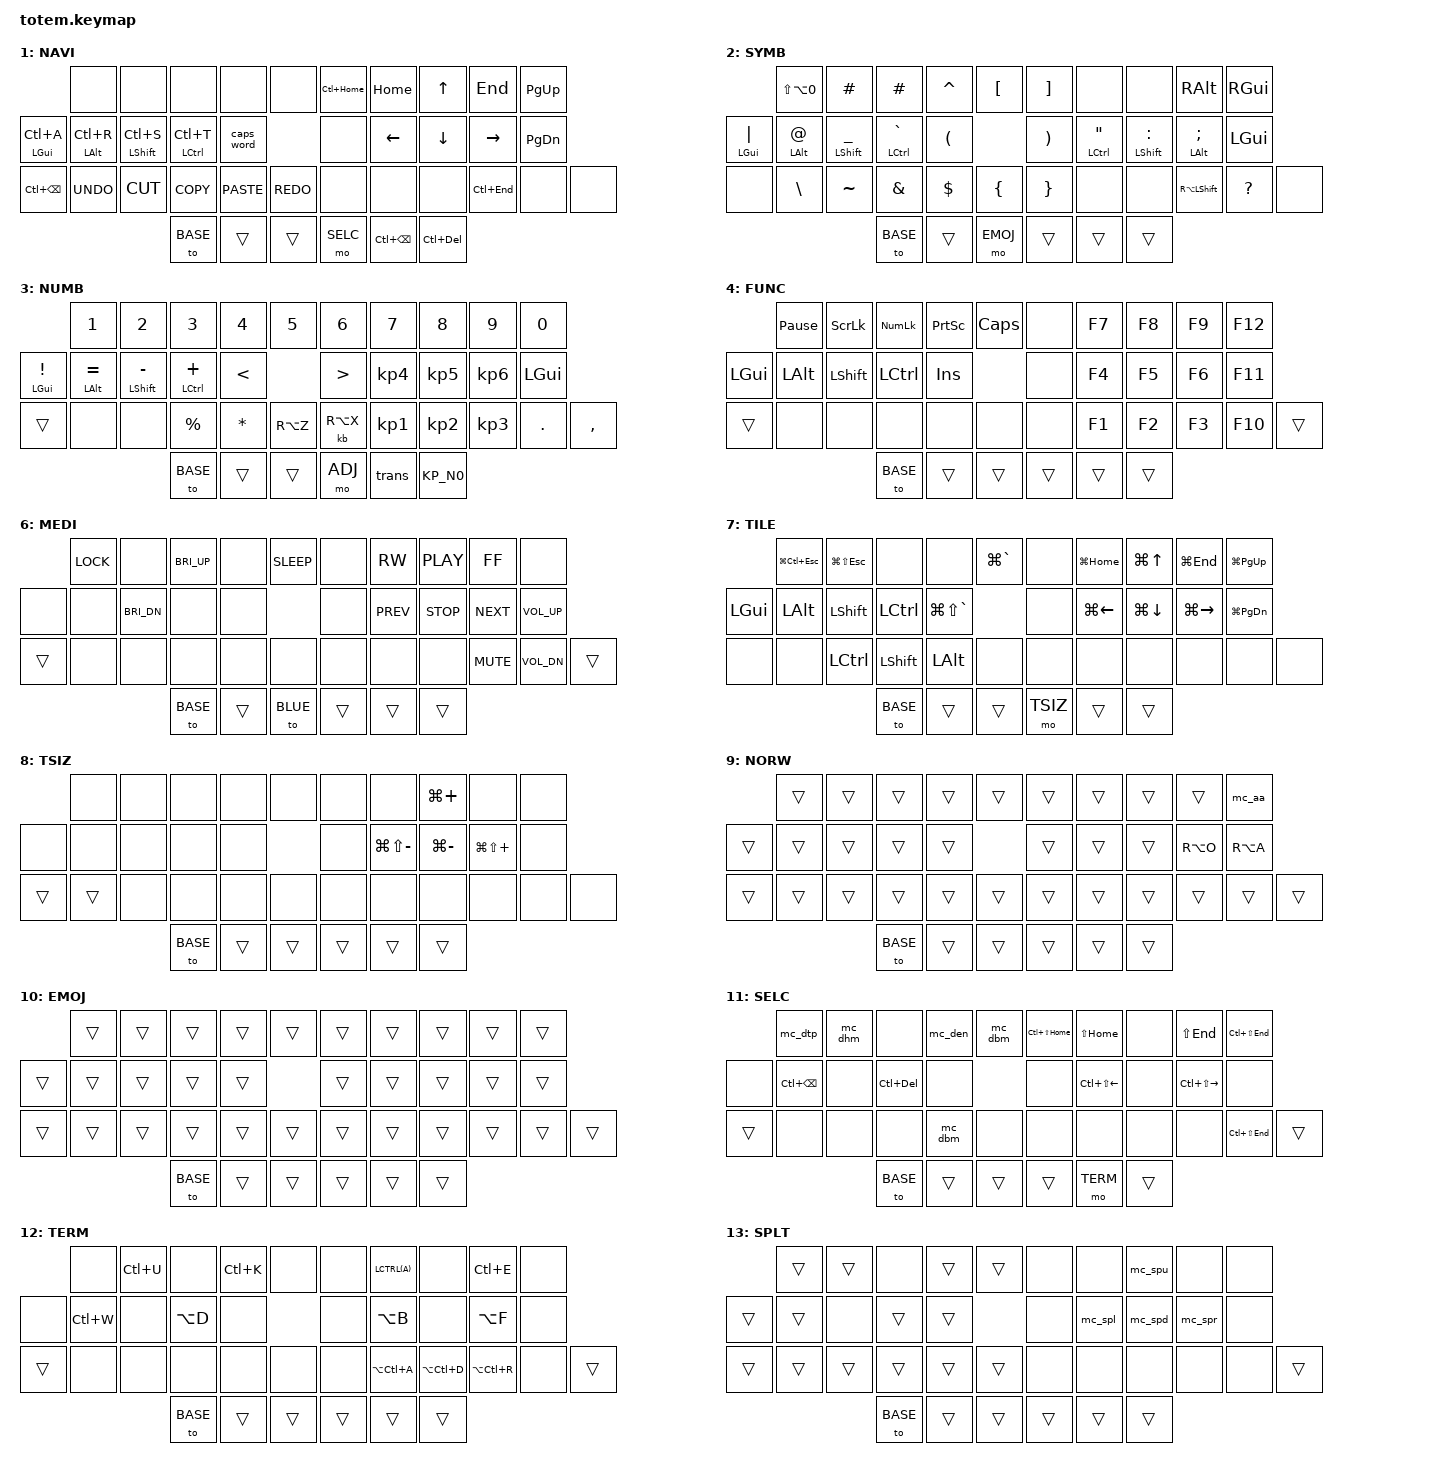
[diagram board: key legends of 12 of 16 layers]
//
//                                                        ▀▀▀▀▀     ▀▀▀▀▀          ▀▀█▀▀
//                                                        ▄▀▀▀▄  ▄  ▄▀▀▀▄  ▄  ▄▀▀▀▄  █  ▄▀▀▀▄
//                                                        █   █  █  █   █  █  █   █  █  █   █
//                                                         ▀▀▀   █   ▀▀▀   █   ▀▀▀   ▀   ▀▀▀
//                                                               █      ▄▄▄█▄▄▄    █   █
//                                                               ▀      █  █  █     █▄█
//                                                             ▀▀▀▀▀    █  █  █      ▀
//                                                                      ▀  ▀  ▀
//
// ▄▄▄▄▄▄▄▄▄▄▄▄▄▄▄▄▄▄▄▄▄▄▄▄▄▄▄▄▄▄▄▄▄▄▄▄▄▄▄▄▄▄▄▄▄▄▄▄▄▄▄▄▄▄▄▄▄▄▄▄▄▄▄▄▄▄▄▄▄▄▄▄▄▄▄▄▄▄▄▄▄▄▄▄▄▄▄▄▄▄▄▄▄▄▄▄▄▄▄▄▄▄▄▄▄▄▄▄▄▄▄▄▄▄▄▄▄▄▄▄▄▄▄▄▄▄▄▄▄▄▄▄▄▄▄▄▄▄▄▄▄▄▄▄▄▄▄▄▄


#include <behaviors.dtsi>
#include <dt-bindings/zmk/keys.h>
#include <dt-bindings/zmk/bt.h>
#include <dt-bindings/zmk/outputs.h>

#define BASE 0
#define NAVI 1
#define SYMB 2
#define NUMB 3
#define FUNC 4
#define CODE 5
#define MEDI 6
#define TILE 7
#define TSIZ 8
#define NORW 9
#define EMOJ 10
#define SELC 11
#define TERM 12
#define SPLT 13
#define QWER 14
#define BLUE 15

&mt {
  quick-tap-ms = <100>;
  global-quick-tap;
  flavor = "tap-preferred";
  tapping-term-ms = <170>;
};

/ {
   behaviors {
        td_rs: tap_dance_reset {
            compatible = "zmk,behavior-tap-dance";
            #binding-cells = <0>;
            tapping-term-ms = <200>;
            bindings = <&none>, <&sys_reset>;
        };
        td_bo: tap_dance_boot {
            compatible = "zmk,behavior-tap-dance";
            #binding-cells = <0>;
            tapping-term-ms = <200>;
            bindings = <&none>, <&bootloader>;
        };
    };

    combos {
            compatible = "zmk,combos";
            combo_esc {
                timeout-ms = <50>;
                key-positions = <0 1>;
                bindings = <&kp ESC>;
            };
    };

    macros {
        mc_aa: macro_aa {
            label = "Å";
            compatible = "zmk,behavior-macro";
            #binding-cells = <1>;
            bindings
                = <&macro_press &kp LGUI>
                , <&macro_tap &kp A>
                , <&macro_release &kp LGUI>
                , <&macro_tap &kp A>
                ;
        };
        vsc: vscode_cmd {
            #binding-cells = <2>;
            compatible = "zmk,behavior-macro-one-param";
            bindings =
                <&kp LC(K)>,
                <&macro_param_1to1 &kp MACRO_PLACEHOLDER>;
        };
        mc_spl: macro_split_left {
            label = "SPLIT_LEFT";
            compatible = "zmk,behavior-macro";
            #binding-cells = <3>;
            bindings
                = <&macro_press &kp LCTRL>
                , <&macro_tap &kp K>
                , <&macro_release &kp LCTRL>
                , <&macro_press &kp LSHFT>
                , <&macro_tap &kp LEFT>
                , <&macro_release &kp LSHFT>
                ;
        };
        mc_spr: macro_split_right {
            label = "SPLIT_RIGHT";
            compatible = "zmk,behavior-macro";
            #binding-cells = <4>;
            bindings
                = <&macro_press &kp LCTRL>
                , <&macro_tap &kp K>
                , <&macro_release &kp LCTRL>
                , <&macro_press &kp LSHFT>
                , <&macro_tap &kp RIGHT>
                , <&macro_release &kp LSHFT>
                ;
        };
        mc_spu macro_split_up {
            label = "SPLIT_UP";
            compatible = "zmk,behavior-macro";
            #binding-cells = <5>;
            bindings
                = <&macro_press &kp LCTRL>
                , <&macro_tap &kp K>
                , <&macro_release &kp LCTRL>
                , <&macro_press &kp LSHFT>
                , <&macro_tap &kp UP>
                , <&macro_release &kp LSHFT>
                ;
        };
        mc_spd: macro_split_down {
            label = "SPLIT_DOWN";
            compatible = "zmk,behavior-macro";
            #binding-cells = <6>;
            bindings
                = <&macro_press &kp LCTRL>
                , <&macro_tap &kp K>
                , <&macro_release &kp LCTRL>
                , <&macro_press &kp LSHFT>
                , <&macro_tap &kp DOWN>
                , <&macro_release &kp LSHFT>
                ;
        };
        mc_zen: macro_zen {
            label = "ZEN";
            compatible = "zmk,behavior-macro";
            #binding-cells = <7>;
            bindings
                = <&macro_press &kp LCTRL>
                , <&macro_tap &kp K>
                , <&macro_release &kp LCTRL>
                , <&macro_tap &kp Z>
                ;
        };
        mc_dhm: macro_del_home {
            label = "DELHOME";
            compatible = "zmk,behavior-macro";
            #binding-cells = <8>;
            bindings
                = <&macro_press &kp LSHFT>
                , <&macro_tap &kp HOME>
                , <&macro_release &kp LSHFT>
                , <&macro_tap &kp DEL>
                ;
        };
        mc_den: macro_del_end {
            label = "DELEND";
            compatible = "zmk,behavior-macro";
            #binding-cells = <9>;
            bindings
                = <&macro_press &kp LSHFT>
                , <&macro_tap &kp END>
                , <&macro_release &kp LSHFT>
                , <&macro_tap &kp DEL>
                ;
        };
        mc_dtp: macro_del_top {
            label = "DELTOP";
            compatible = "zmk,behavior-macro";
            #binding-cells = <10>;
            bindings
                = <&macro_press &kp LSHFT>
                , <&macro_press &kp LCTRL>
                , <&macro_tap &kp HOME>
                , <&macro_release &kp LCTRL>
                , <&macro_release &kp LSHFT>
                , <&macro_tap &kp DEL>
                ;
        };
        mc_dbm: macro_del_btm {
            label = "DELEND";
            compatible = "zmk,behavior-macro";
            #binding-cells = <11>;
            bindings
                = <&macro_press &kp LSHFT>
                , <&macro_press &kp LCTRL>
                , <&macro_tap &kp END>
                , <&macro_release &kp LCTRL>
                , <&macro_release &kp LSHFT>
                , <&macro_tap &kp DEL>
                ;
        };
        mc_sav: macro_save_file {
            label = "SAVE_FILE";
            compatible = "zmk,behavior-macro";
            #binding-cells = <12>;
            bindings
                = <&macro_press &kp LCTRL>
                , <&macro_tap &kp K>
                , <&macro_release &kp LCTRL>
                , <&macro_tap &kp S>
                ;
        };
    };

        keymap {
                compatible = "zmk,keymap";
// ▄▄▄▄▄▄▄▄▄▄▄▄▄▄▄▄▄▄▄▄▄▄▄▄▄▄▄▄▄▄▄▄▄▄▄▄▄▄▄▄▄▄▄▄▄▄▄▄▄▄▄▄▄▄▄▄▄▄▄▄▄▄▄▄▄▄▄▄▄▄▄▄▄▄▄▄▄▄▄▄▄▄▄▄▄▄▄▄▄▄▄▄▄▄▄▄▄▄▄▄▄▄▄▄▄▄▄▄▄▄▄▄▄▄▄▄▄▄▄▄▄▄▄▄▄▄▄▄▄▄▄▄▄▄▄▄▄▄▄▄▄▄▄▄▄▄▄▄▄

                base_layer {
// ┏━━━━━━━━━━━━━━━━━━━━━━━━━━━━━━━━━━━━━━━┓
label= "BASE"                              ;
// ┗━━━━━━━━━━━━━━━━━━━━━━━━━━━━━━━━━━━━━━━┛
//             ┏━━━━━━━━━━━┳━━━━━━━━━━━┳━━━━━━━━━━━┳━━━━━━━━━━━┳━━━━━━━━━━━┓   ┏━━━━━━━━━━━┳━━━━━━━━━━━┳━━━━━━━━━━━┳━━━━━━━━━━━┳━━━━━━━━━━━┓
//             ┃     Q     ┃     W     ┃     F     ┃     P     ┃     B     ┃   ┃     J     ┃     L     ┃     O     ┃     Y     ┃     '     ┃
//             ┣━━━━━━━━━━━╋━━━━━━━━━━━╋━━━━━━━━━━━╋━━━━━━━━━━━╋━━━━━━━━━━━┫   ┣━━━━━━━━━━━╋━━━━━━━━━━━╋━━━━━━━━━━━╋━━━━━━━━━━━╋━━━━━━━━━━━┫
//             ┃     A     ┃     R     ┃     S     ┃     T     ┃     G     ┃   ┃     M     ┃     N     ┃     E     ┃     I     ┃     U     ┃
// ┏━━━━━━━━━━━╋━━━━━━━━━━━╋━━━━━━━━━━━╋━━━━━━━━━━━╋━━━━━━━━━━━╋━━━━━━━━━━━┫   ┣━━━━━━━━━━━╋━━━━━━━━━━━╋━━━━━━━━━━━╋━━━━━━━━━━━╋━━━━━━━━━━━╋━━━━━━━━━━━┓
// ┃    BSPC   ┃     Z     ┃     X     ┃     C     ┃     D     ┃     V     ┃   ┃     K     ┃     H     ┃     ,     ┃     .     ┃     /     ┃           ┃
// ┗━━━━━━━━━━━┻━━━━━━━━━━━┻━━━━━━━━━━━╋━━━━━━━━━━━╋━━━━━━━━━━━╋━━━━━━━━━━━┫   ┣━━━━━━━━━━━╋━━━━━━━━━━━╋━━━━━━━━━━━╋━━━━━━━━━━━┻━━━━━━━━━━━┻━━━━━━━━━━━┛
//                                     ┃    ESC    ┃    SPC    ┃    TAB    ┃   ┃   ENTER   ┃    BSPC   ┃    DEL    ┃
//                                     ┗━━━━━━━━━━━┻━━━━━━━━━━━┻━━━━━━━━━━━┛   ┗━━━━━━━━━━━┻━━━━━━━━━━━┻━━━━━━━━━━━┛
//             ┏━━━━━━━━━━━┳━━━━━━━━━━━┳━━━━━━━━━━━┳━━━━━━━━━━━┳━━━━━━━━━━━┓   ┏━━━━━━━━━━━┳━━━━━━━━━━━┳━━━━━━━━━━━┳━━━━━━━━━━━┳━━━━━━━━━━━┓
//             ┃     ⌘R    ┃    ⌥R     ┃    ⇧R     ┃    ^R     ┃           ┃   ┃           ┃    ^R     ┃    ⇧R     ┃    ⌥R     ┃     ⌘R    ┃
//             ┣━━━━━━━━━━━╋━━━━━━━━━━━╋━━━━━━━━━━━╋━━━━━━━━━━━╋━━━━━━━━━━━┫   ┣━━━━━━━━━━━╋━━━━━━━━━━━╋━━━━━━━━━━━╋━━━━━━━━━━━╋━━━━━━━━━━━┫
//             ┃     ⌘     ┃    ⎇     ┃     ⇧     ┃     ^     ┃           ┃   ┃           ┃     ^     ┃     ⇧     ┃    ⎇     ┃     ⌘     ┃
// ┏━━━━━━━━━━━╋━━━━━━━━━━━╋━━━━━━━━━━━╋━━━━━━━━━━━╋━━━━━━━━━━━╋━━━━━━━━━━━┫   ┣━━━━━━━━━━━╋━━━━━━━━━━━╋━━━━━━━━━━━╋━━━━━━━━━━━╋━━━━━━━━━━━╋━━━━━━━━━━━┓
// ┃           ┃   TILE    ┃     ⎄     ┃   MEH     ┃   HYP     ┃           ┃   ┃           ┃    HYP    ┃    MEH    ┃     ⎄     ┃    MED    ┃    NOR    ┃
// ┗━━━━━━━━━━━┻━━━━━━━━━━━┻━━━━━━━━━━━╋━━━━━━━━━━━╋━━━━━━━━━━━╋━━━━━━━━━━━┫   ┣━━━━━━━━━━━╋━━━━━━━━━━━╋━━━━━━━━━━━╋━━━━━━━━━━━┻━━━━━━━━━━━┻━━━━━━━━━━━┛
//                                     ┃    FUN    ┃    NUM    ┃    NAV    ┃   ┃    SYM    ┃    NUM    ┃   CODE    ┃
//                                     ┗━━━━━━━━━━━┻━━━━━━━━━━━┻━━━━━━━━━━━┛   ┗━━━━━━━━━━━┻━━━━━━━━━━━┻━━━━━━━━━━━┛
 bindings = <
// ╷           ╷           ╷           ╷           ╷             ╷         ╷   ╷           ╷           ╷           ╷           ╷           ╷           ╷

                &mt RGUI Q  &mt RALT W  &mt RSHFT F &mt RCTRL P    &kp B          &kp J        &mt RCTRL L &mt RSHFT O &mt RALT Y  &mt RGUI SQT
                &mt LGUI A  &mt LALT R  &mt LSHFT S &mt LCTRL T    &kp G          &kp M        &mt LCTRL N &mt LSHFT E &mt LALT I  &mt LGUI U
    &kp BSPC    &lt TILE Z  &mt LS(RALT) X  &mt LS(LA(LCTRL)) C  &mt LS(LA(LC(LG))) D  &kp V  &kp K  &mt LS(LA(LC(LG))) H  &mt LS(LA(LCTRL)) COMMA  &mt LS(RALT) DOT  &lt MEDI FSLH  &mo NORW
                                        &lt FUNC ESC     &lt NUMB SPACE &lt NAVI TAB   &lt SYMB RET &lt NUMB BSPC    &lt CODE DEL
                        >;
                };

// ▄▄▄▄▄▄▄▄▄▄▄▄▄▄▄▄▄▄▄▄▄▄▄▄▄▄▄▄▄▄▄▄▄▄▄▄▄▄▄▄▄▄▄▄▄▄▄▄▄▄▄▄▄▄▄▄▄▄▄▄▄▄▄▄▄▄▄▄▄▄▄▄▄▄▄▄▄▄▄▄▄▄▄▄▄▄▄▄▄▄▄▄▄▄▄▄▄▄▄▄▄▄▄▄▄▄▄▄▄▄▄▄▄▄▄▄▄▄▄▄▄▄▄▄▄▄▄▄▄▄▄▄▄▄▄▄▄▄▄▄▄▄▄▄▄▄▄▄▄


                nav_layer {
// ┏━━━━━━━━━━━━━━━━━━━━━━━━━━━━━━━━━━━━━━━┓
label= "NAVI"                              ;
// ┗━━━━━━━━━━━━━━━━━━━━━━━━━━━━━━━━━━━━━━━┛
//             ┏━━━━━━━━━━━┳━━━━━━━━━━━┳━━━━━━━━━━━┳━━━━━━━━━━━┳━━━━━━━━━━━┓   ┏━━━━━━━━━━━┳━━━━━━━━━━━┳━━━━━━━━━━━┳━━━━━━━━━━━┳━━━━━━━━━━━┓
//             ┃           ┃           ┃           ┃           ┃           ┃   ┃    TOP    ┃   HOME    ┃    UP     ┃   END     ┃   PG_UP   ┃
//             ┣━━━━━━━━━━━╋━━━━━━━━━━━╋━━━━━━━━━━━╋━━━━━━━━━━━╋━━━━━━━━━━━┫   ┣━━━━━━━━━━━╋━━━━━━━━━━━╋━━━━━━━━━━━╋━━━━━━━━━━━╋━━━━━━━━━━━┫
//             ┃   SELECT  ┃   RELOAD  ┃    SAVE   ┃  NEW TAB  ┃ CAPS WORD ┃   ┃           ┃   LEFT    ┃    DOWN   ┃   RIGHT   ┃   PG_DN   ┃
// ┏━━━━━━━━━━━╋━━━━━━━━━━━╋━━━━━━━━━━━╋━━━━━━━━━━━╋━━━━━━━━━━━╋━━━━━━━━━━━┫   ┣━━━━━━━━━━━╋━━━━━━━━━━━╋━━━━━━━━━━━╋━━━━━━━━━━━╋━━━━━━━━━━━╋━━━━━━━━━━━┓
// ┃^BACKSPACE ┃    UNDO   ┃    CUT    ┃   COPY    ┃   PASTE   ┃   REDO    ┃   ┃           ┃           ┃           ┃   BTTM    ┃           ┃           ┃
// ┗━━━━━━━━━━━┻━━━━━━━━━━━┻━━━━━━━━━━━╋━━━━━━━━━━━╋━━━━━━━━━━━╋━━━━━━━━━━━┫   ┣━━━━━━━━━━━╋━━━━━━━━━━━╋━━━━━━━━━━━╋━━━━━━━━━━━┻━━━━━━━━━━━┻━━━━━━━━━━━┛
//                                     ┃           ┃           ┃           ┃   ┃   SELECT  ┃^BACKSPACE ┃   ^ DEL   ┃
//                                     ┗━━━━━━━━━━━┻━━━━━━━━━━━┻━━━━━━━━━━━┛   ┗━━━━━━━━━━━┻━━━━━━━━━━━┻━━━━━━━━━━━┛
 bindings = <
// ╷           ╷           ╷           ╷           ╷           ╷           ╷   ╷           ╷           ╷           ╷           ╷           ╷           ╷

                &none       &none       &none       &none       &none           &kp LC(HOME)  &kp HOME  &kp UP      &kp END     &kp PG_UP
       &mt LGUI LC(A)  &mt LALT LC(R)  &mt LSHFT LC(S)  &mt LCTRL LC(T)  &caps_word      &none  &kp LEFT  &kp DOWN  &kp RIGHT   &kp PG_DN
    &kp LC(BSPC)  &kp K_UNDO  &kp K_CUT  &kp K_COPY  &kp K_PASTE  &kp K_REDO    &none       &none        &none      &kp LC(END)  &none       &none
                                        &to BASE    &trans      &trans          &mo SELC    &kp LC(BSPC)  &kp LC(DEL)
                        >;
                };

// ▄▄▄▄▄▄▄▄▄▄▄▄▄▄▄▄▄▄▄▄▄▄▄▄▄▄▄▄▄▄▄▄▄▄▄▄▄▄▄▄▄▄▄▄▄▄▄▄▄▄▄▄▄▄▄▄▄▄▄▄▄▄▄▄▄▄▄▄▄▄▄▄▄▄▄▄▄▄▄▄▄▄▄▄▄▄▄▄▄▄▄▄▄▄▄▄▄▄▄▄▄▄▄▄▄▄▄▄▄▄▄▄▄▄▄▄▄▄▄▄▄▄▄▄▄▄▄▄▄▄▄▄▄▄▄▄▄▄▄▄▄▄▄▄▄▄▄▄▄


                symbol_layer {
// ┏━━━━━━━━━━━━━━━━━━━━━━━━━━━━━━━━━━━━━━━┓
label= "SYMB"                              ;
// ┗━━━━━━━━━━━━━━━━━━━━━━━━━━━━━━━━━━━━━━━┛
//             ┏━━━━━━━━━━━┳━━━━━━━━━━━┳━━━━━━━━━━━┳━━━━━━━━━━━┳━━━━━━━━━━━┓   ┏━━━━━━━━━━━┳━━━━━━━━━━━┳━━━━━━━━━━━┳━━━━━━━━━━━┳━━━━━━━━━━━┓
//             ┃     °     ┃     #     ┃     £     ┃     ˆ     ┃     [     ┃   ┃     ]     ┃           ┃           ┃           ┃           ┃
//             ┣━━━━━━━━━━━╋━━━━━━━━━━━╋━━━━━━━━━━━╋━━━━━━━━━━━╋━━━━━━━━━━━┫   ┣━━━━━━━━━━━╋━━━━━━━━━━━╋━━━━━━━━━━━╋━━━━━━━━━━━╋━━━━━━━━━━━┫
//             ┃     |     ┃     @     ┃     _     ┃     `     ┃     (     ┃   ┃     )     ┃     "     ┃     :     ┃     ;     ┃           ┃
// ┏━━━━━━━━━━━╋━━━━━━━━━━━╋━━━━━━━━━━━╋━━━━━━━━━━━╋━━━━━━━━━━━╋━━━━━━━━━━━┫   ┣━━━━━━━━━━━╋━━━━━━━━━━━╋━━━━━━━━━━━╋━━━━━━━━━━━╋━━━━━━━━━━━╋━━━━━━━━━━━┓
// ┃           ┃     \     ┃     ~     ┃     &     ┃     $     ┃     {     ┃   ┃     }     ┃           ┃           ┃           ┃     ?     ┃           ┃
// ┗━━━━━━━━━━━┻━━━━━━━━━━━┻━━━━━━━━━━━╋━━━━━━━━━━━╋━━━━━━━━━━━╋━━━━━━━━━━━┫   ┣━━━━━━━━━━━╋━━━━━━━━━━━╋━━━━━━━━━━━╋━━━━━━━━━━━┻━━━━━━━━━━━┻━━━━━━━━━━━┛
//                                     ┃           ┃           ┃   EMOJI   ┃   ┃           ┃           ┃           ┃
//                                     ┗━━━━━━━━━━━┻━━━━━━━━━━━┻━━━━━━━━━━━┛   ┗━━━━━━━━━━━┻━━━━━━━━━━━┻━━━━━━━━━━━┛
 bindings = <
// ╷           ╷           ╷           ╷           ╷           ╷           ╷   ╷           ╷           ╷           ╷           ╷           ╷           ╷

                &kp LS(LA(0)) &kp HASH  &kp POUND   &kp CARET   &kp LBKT        &kp RBKT    &none       &none       &kp RALT    &kp RGUI
       &mt LGUI PIPE  &mt LALT AT  &mt LSHFT UNDER  &mt LCTRL GRAVE  &kp LPAR   &kp RPAR  &mt LCTRL DQT  &mt LSHFT COLON  &mt LALT SEMI  &kp LGUI
    &none       &kp BSLH    &kp TILDE   &kp AMPS    &kp DLLR    &kp LBRC        &kp RBRC    &none       &none       &kp RA(LSHFT)  &kp QMARK   &none
                                        &to BASE    &trans      &mo EMOJ        &trans      &trans      &trans
                        >;
                };

// ▄▄▄▄▄▄▄▄▄▄▄▄▄▄▄▄▄▄▄▄▄▄▄▄▄▄▄▄▄▄▄▄▄▄▄▄▄▄▄▄▄▄▄▄▄▄▄▄▄▄▄▄▄▄▄▄▄▄▄▄▄▄▄▄▄▄▄▄▄▄▄▄▄▄▄▄▄▄▄▄▄▄▄▄▄▄▄▄▄▄▄▄▄▄▄▄▄▄▄▄▄▄▄▄▄▄▄▄▄▄▄▄▄▄▄▄▄▄▄▄▄▄▄▄▄▄▄▄▄▄▄▄▄▄▄▄▄▄▄▄▄▄▄▄▄▄▄▄▄

                number_layer {
// ┏━━━━━━━━━━━━━━━━━━━━━━━━━━━━━━━━━━━━━━━┓
label= "NUMB"                              ;
// ┗━━━━━━━━━━━━━━━━━━━━━━━━━━━━━━━━━━━━━━━┛
//             ┏━━━━━━━━━━━┳━━━━━━━━━━━┳━━━━━━━━━━━┳━━━━━━━━━━━┳━━━━━━━━━━━┓   ┏━━━━━━━━━━━┳━━━━━━━━━━━┳━━━━━━━━━━━┳━━━━━━━━━━━┳━━━━━━━━━━━┓
//             ┃     1     ┃     2     ┃     3     ┃     4     ┃     5     ┃   ┃     6     ┃     7     ┃     8     ┃     9     ┃     0     ┃
//             ┣━━━━━━━━━━━╋━━━━━━━━━━━╋━━━━━━━━━━━╋━━━━━━━━━━━╋━━━━━━━━━━━┫   ┣━━━━━━━━━━━╋━━━━━━━━━━━╋━━━━━━━━━━━╋━━━━━━━━━━━╋━━━━━━━━━━━┫
//             ┃     !     ┃     =     ┃     -     ┃     +     ┃     <     ┃   ┃     >     ┃     4     ┃     5     ┃     6     ┃           ┃
// ┏━━━━━━━━━━━╋━━━━━━━━━━━╋━━━━━━━━━━━╋━━━━━━━━━━━╋━━━━━━━━━━━╋━━━━━━━━━━━┫   ┣━━━━━━━━━━━╋━━━━━━━━━━━╋━━━━━━━━━━━╋━━━━━━━━━━━╋━━━━━━━━━━━╋━━━━━━━━━━━┓
// ┃           ┃           ┃           ┃     %     ┃     *     ┃     «     ┃   ┃     »     ┃     1     ┃     2     ┃     3     ┃     .     ┃     ,     ┃
// ┗━━━━━━━━━━━┻━━━━━━━━━━━┻━━━━━━━━━━━╋━━━━━━━━━━━╋━━━━━━━━━━━╋━━━━━━━━━━━┫   ┣━━━━━━━━━━━╋━━━━━━━━━━━╋━━━━━━━━━━━╋━━━━━━━━━━━┻━━━━━━━━━━━┻━━━━━━━━━━━┛
//                                     ┃           ┃           ┃           ┃   ┃           ┃           ┃     0     ┃
//                                     ┗━━━━━━━━━━━┻━━━━━━━━━━━┻━━━━━━━━━━━┛   ┗━━━━━━━━━━━┻━━━━━━━━━━━┻━━━━━━━━━━━┛
 bindings = <
// ╷           ╷           ╷           ╷           ╷           ╷           ╷   ╷           ╷           ╷           ╷           ╷           ╷           ╷

                &kp N1        &kp N2         &kp N3          &kp N4      &kp N5     &kp N6     &kp N7      &kp N8      &kp N9      &kp N0
            &mt LGUI EXCL  &mt LALT EQUAL  &mt LSHFT MINUS   &mt LCTRL PLUS  &kp LT  &kp GT    &kp KP_N4   &kp KP_N5   &kp KP_N6   &kp LGUI
    &trans      &none         &none         &kp PERCENT     &kp STAR    &kp RA(Z)  &kb RA(X)  &kp KP_N1   &kp KP_N2   &kp KP_N3   &kp DOT       &kp COMMA
                                             &to BASE        &trans      &trans     &mo ADJ    &kp trans   &KP_N0
                        >;
                };

// ▄▄▄▄▄▄▄▄▄▄▄▄▄▄▄▄▄▄▄▄▄▄▄▄▄▄▄▄▄▄▄▄▄▄▄▄▄▄▄▄▄▄▄▄▄▄▄▄▄▄▄▄▄▄▄▄▄▄▄▄▄▄▄▄▄▄▄▄▄▄▄▄▄▄▄▄▄▄▄▄▄▄▄▄▄▄▄▄▄▄▄▄▄▄▄▄▄▄▄▄▄▄▄▄▄▄▄▄▄▄▄▄▄▄▄▄▄▄▄▄▄▄▄▄▄▄▄▄▄▄▄▄▄▄▄▄▄▄▄▄▄▄▄▄▄▄▄▄▄

                function_layer {
// ┏━━━━━━━━━━━━━━━━━━━━━━━━━━━━━━━━━━━━━━━┓
label= "FUNC"                              ;
// ┗━━━━━━━━━━━━━━━━━━━━━━━━━━━━━━━━━━━━━━━┛
//             ┏━━━━━━━━━━━┳━━━━━━━━━━━┳━━━━━━━━━━━┳━━━━━━━━━━━┳━━━━━━━━━━━┓   ┏━━━━━━━━━━━┳━━━━━━━━━━━┳━━━━━━━━━━━┳━━━━━━━━━━━┳━━━━━━━━━━━┓
//             ┃   Pause   ┃   Scroll  ┃  Numlock  ┃   Print   ┃    Caps   ┃   ┃           ┃    F7     ┃    F8     ┃    F9     ┃    F12    ┃
//             ┣━━━━━━━━━━━╋━━━━━━━━━━━╋━━━━━━━━━━━╋━━━━━━━━━━━╋━━━━━━━━━━━┫   ┣━━━━━━━━━━━╋━━━━━━━━━━━╋━━━━━━━━━━━╋━━━━━━━━━━━╋━━━━━━━━━━━┫
//             ┃    GUI    ┃    ALT    ┃   SHIFT   ┃   CTRL    ┃    Ins    ┃   ┃           ┃    F4     ┃    F5     ┃    F6     ┃    F11    ┃
// ┏━━━━━━━━━━━╋━━━━━━━━━━━╋━━━━━━━━━━━╋━━━━━━━━━━━╋━━━━━━━━━━━╋━━━━━━━━━━━┫   ┣━━━━━━━━━━━╋━━━━━━━━━━━╋━━━━━━━━━━━╋━━━━━━━━━━━╋━━━━━━━━━━━╋━━━━━━━━━━━┓
// ┃           ┃           ┃           ┃           ┃           ┃           ┃   ┃           ┃    F1     ┃    F2     ┃    F3     ┃    F10    ┃           ┃
// ┗━━━━━━━━━━━┻━━━━━━━━━━━┻━━━━━━━━━━━╋━━━━━━━━━━━╋━━━━━━━━━━━╋━━━━━━━━━━━┫   ┣━━━━━━━━━━━╋━━━━━━━━━━━╋━━━━━━━━━━━╋━━━━━━━━━━━┻━━━━━━━━━━━┻━━━━━━━━━━━┛
//                                     ┃           ┃           ┃           ┃   ┃           ┃           ┃           ┃
//                                     ┗━━━━━━━━━━━┻━━━━━━━━━━━┻━━━━━━━━━━━┛   ┗━━━━━━━━━━━┻━━━━━━━━━━━┻━━━━━━━━━━━┛
 bindings = <
// ╷           ╷           ╷           ╷           ╷           ╷           ╷   ╷           ╷           ╷           ╷           ╷           ╷           ╷

                &kp PAUSE_BREAK &kp SLCK &kp KP_NUM &kp PSCRN   &kp CAPS        &none       &kp F7      &kp F8      &kp F9      &kp F12
                &kp LGUI    &kp LALT    &kp LSHFT   &kp LCTRL   &kp INS         &none       &kp F4      &kp F5      &kp F6      &kp F11
    &trans      &none       &none       &none       &none       &none           &none       &kp F1      &kp F2      &kp F3      &kp F10     &trans
                                        &to BASE    &trans      &trans          &trans      &trans      &trans
                        >;
                };

// ▄▄▄▄▄▄▄▄▄▄▄▄▄▄▄▄▄▄▄▄▄▄▄▄▄▄▄▄▄▄▄▄▄▄▄▄▄▄▄▄▄▄▄▄▄▄▄▄▄▄▄▄▄▄▄▄▄▄▄▄▄▄▄▄▄▄▄▄▄▄▄▄▄▄▄▄▄▄▄▄▄▄▄▄▄▄▄▄▄▄▄▄▄▄▄▄▄▄▄▄▄▄▄▄▄▄▄▄▄▄▄▄▄▄▄▄▄▄▄▄▄▄▄▄▄▄▄▄▄▄▄▄▄▄▄▄▄▄▄▄▄▄▄▄▄▄▄▄▄

                code_layer {
// ┏━━━━━━━━━━━━━━━━━━━━━━━━━━━━━━━━━━━━━━━┓
label= "CODE"                              ;
// ┗━━━━━━━━━━━━━━━━━━━━━━━━━━━━━━━━━━━━━━━┛
//             ┏━━━━━━━━━━━┳━━━━━━━━━━━┳━━━━━━━━━━━┳━━━━━━━━━━━┳━━━━━━━━━━━┓   ┏━━━━━━━━━━━┳━━━━━━━━━━━┳━━━━━━━━━━━┳━━━━━━━━━━━┳━━━━━━━━━━━┓
//             ┃   QWERTY  ┃           ┃           ┃           ┃           ┃   ┃           ┃           ┃  DUPE UP  ┃           ┃           ┃
//             ┣━━━━━━━━━━━╋━━━━━━━━━━━╋━━━━━━━━━━━╋━━━━━━━━━━━╋━━━━━━━━━━━┫   ┣━━━━━━━━━━━╋━━━━━━━━━━━╋━━━━━━━━━━━╋━━━━━━━━━━━╋━━━━━━━━━━━┫
//             ┃           ┃           ┃   SAVE    ┃           ┃           ┃   ┃           ┃           ┃ DUPE DOWN ┃           ┃           ┃
// ┏━━━━━━━━━━━╋━━━━━━━━━━━╋━━━━━━━━━━━╋━━━━━━━━━━━╋━━━━━━━━━━━╋━━━━━━━━━━━┫   ┣━━━━━━━━━━━╋━━━━━━━━━━━╋━━━━━━━━━━━╋━━━━━━━━━━━╋━━━━━━━━━━━╋━━━━━━━━━━━┓
// ┃  SIDEBAR  ┃    ZEN    ┃           ┃           ┃ Move Term ┃  Terminal ┃   ┃           ┃           ┃           ┃           ┃           ┃  COMMENT  ┃
// ┗━━━━━━━━━━━┻━━━━━━━━━━━┻━━━━━━━━━━━╋━━━━━━━━━━━╋━━━━━━━━━━━╋━━━━━━━━━━━┫   ┣━━━━━━━━━━━╋━━━━━━━━━━━╋━━━━━━━━━━━╋━━━━━━━━━━━┻━━━━━━━━━━━┻━━━━━━━━━━━┛
//                                     ┃           ┃           ┃           ┃   ┃   LAUNCH  ┃    RUN    ┃   SPLIT   ┃
//                                     ┗━━━━━━━━━━━┻━━━━━━━━━━━┻━━━━━━━━━━━┛   ┗━━━━━━━━━━━┻━━━━━━━━━━━┻━━━━━━━━━━━┛
 bindings = <
// ╷           ╷           ╷           ╷           ╷           ╷           ╷   ╷           ╷           ╷           ╷           ╷           ╷           ╷

                &to QWER    &none       &none       &none       &none           &none       &none    &kp LA(LC(LS(UP)))    &none  &none
                &none       &none       &vsc S     &none       &none           &none       &none    &kp LA(LC(LS(DOWN)))  &none  &none
    &kp LC(BSLH)  &mc_zen   &none       &none    &kp LA(LC(LS(E)))  &kp LC(GRAVE)  &none    &none       &none       &none       &none       &kp LC(FSLH)
                                        &to BASE    &trans      &trans          &kp LG(A)   &kp LA(F12)  &MO SPLT
                        >;
                };

// ▄▄▄▄▄▄▄▄▄▄▄▄▄▄▄▄▄▄▄▄▄▄▄▄▄▄▄▄▄▄▄▄▄▄▄▄▄▄▄▄▄▄▄▄▄▄▄▄▄▄▄▄▄▄▄▄▄▄▄▄▄▄▄▄▄▄▄▄▄▄▄▄▄▄▄▄▄▄▄▄▄▄▄▄▄▄▄▄▄▄▄▄▄▄▄▄▄▄▄▄▄▄▄▄▄▄▄▄▄▄▄▄▄▄▄▄▄▄▄▄▄▄▄▄▄▄▄▄▄▄▄▄▄▄▄▄▄▄▄▄▄▄▄▄▄▄▄▄▄

                media_layer {
// ┏━━━━━━━━━━━━━━━━━━━━━━━━━━━━━━━━━━━━━━━┓
label= "MEDI"                              ;
// ┗━━━━━━━━━━━━━━━━━━━━━━━━━━━━━━━━━━━━━━━┛
//             ┏━━━━━━━━━━━┳━━━━━━━━━━━┳━━━━━━━━━━━┳━━━━━━━━━━━┳━━━━━━━━━━━┓   ┏━━━━━━━━━━━┳━━━━━━━━━━━┳━━━━━━━━━━━┳━━━━━━━━━━━┳━━━━━━━━━━━┓
//             ┃    LOCK   ┃           ┃  BRIGHT+  ┃           ┃   SLEEP   ┃   ┃           ┃   REWIND  ┃    PLAY   ┃  FORWARD  ┃           ┃
//             ┣━━━━━━━━━━━╋━━━━━━━━━━━╋━━━━━━━━━━━╋━━━━━━━━━━━╋━━━━━━━━━━━┫   ┣━━━━━━━━━━━╋━━━━━━━━━━━╋━━━━━━━━━━━╋━━━━━━━━━━━╋━━━━━━━━━━━┫
//             ┃           ┃           ┃  BRIGHT-  ┃           ┃           ┃   ┃           ┃   LAST    ┃    STOP   ┃    NEXT   ┃    VOL+   ┃
// ┏━━━━━━━━━━━╋━━━━━━━━━━━╋━━━━━━━━━━━╋━━━━━━━━━━━╋━━━━━━━━━━━╋━━━━━━━━━━━┫   ┣━━━━━━━━━━━╋━━━━━━━━━━━╋━━━━━━━━━━━╋━━━━━━━━━━━╋━━━━━━━━━━━╋━━━━━━━━━━━┓
// ┃           ┃           ┃           ┃           ┃           ┃           ┃   ┃           ┃           ┃           ┃    MUTE   ┃    VOL-   ┃           ┃
// ┗━━━━━━━━━━━┻━━━━━━━━━━━┻━━━━━━━━━━━╋━━━━━━━━━━━╋━━━━━━━━━━━╋━━━━━━━━━━━┫   ┣━━━━━━━━━━━╋━━━━━━━━━━━╋━━━━━━━━━━━╋━━━━━━━━━━━┻━━━━━━━━━━━┻━━━━━━━━━━━┛
//                                     ┃           ┃           ┃ BLUETOOTH ┃   ┃           ┃           ┃           ┃
//                                     ┗━━━━━━━━━━━┻━━━━━━━━━━━┻━━━━━━━━━━━┛   ┗━━━━━━━━━━━┻━━━━━━━━━━━┻━━━━━━━━━━━┛
 bindings = <
// ╷           ╷           ╷           ╷           ╷           ╷           ╷   ╷           ╷           ╷           ╷           ╷           ╷           ╷

                &kp K_LOCK  &none       &kp C_BRI_UP  &none     &kp C_SLEEP     &none       &kp C_RW    &kp C_PLAY  &kp C_FF    &none
                &none       &none       &kp C_BRI_DN  &none     &none           &none       &kp C_PREV  &kp C_STOP  &kp C_NEXT  &kp C_VOL_UP
    &trans      &none       &none       &none       &none       &none           &none       &none       &none       &kp C_MUTE  &kp C_VOL_DN    &trans
                                        &to BASE    &trans      &to BLUE        &trans      &trans      &trans
                        >;
                };

// ▄▄▄▄▄▄▄▄▄▄▄▄▄▄▄▄▄▄▄▄▄▄▄▄▄▄▄▄▄▄▄▄▄▄▄▄▄▄▄▄▄▄▄▄▄▄▄▄▄▄▄▄▄▄▄▄▄▄▄▄▄▄▄▄▄▄▄▄▄▄▄▄▄▄▄▄▄▄▄▄▄▄▄▄▄▄▄▄▄▄▄▄▄▄▄▄▄▄▄▄▄▄▄▄▄▄▄▄▄▄▄▄▄▄▄▄▄▄▄▄▄▄▄▄▄▄▄▄▄▄▄▄▄▄▄▄▄▄▄▄▄▄▄▄▄▄▄▄▄

                tiling_layer {
// ┏━━━━━━━━━━━━━━━━━━━━━━━━━━━━━━━━━━━━━━━┓
label= "TILE"                              ;
// ┗━━━━━━━━━━━━━━━━━━━━━━━━━━━━━━━━━━━━━━━┛
//             ┏━━━━━━━━━━━┳━━━━━━━━━━━┳━━━━━━━━━━━┳━━━━━━━━━━━┳━━━━━━━━━━━┓   ┏━━━━━━━━━━━┳━━━━━━━━━━━┳━━━━━━━━━━━┳━━━━━━━━━━━┳━━━━━━━━━━━┓
//             ┃  SCRATCH  ┃ SCRTCHALL ┃           ┃           ┃  META `   ┃   ┃           ┃ META HOME ┃  META UP  ┃ META END  ┃ META PGUP ┃
//             ┣━━━━━━━━━━━╋━━━━━━━━━━━╋━━━━━━━━━━━╋━━━━━━━━━━━╋━━━━━━━━━━━┫   ┣━━━━━━━━━━━╋━━━━━━━━━━━╋━━━━━━━━━━━╋━━━━━━━━━━━╋━━━━━━━━━━━┫
//             ┃           ┃           ┃           ┃           ┃ META SF ` ┃   ┃           ┃ META LEFT ┃ META DOWN ┃ METARIGHT ┃ META PGDN ┃
// ┏━━━━━━━━━━━╋━━━━━━━━━━━╋━━━━━━━━━━━╋━━━━━━━━━━━╋━━━━━━━━━━━╋━━━━━━━━━━━┫   ┣━━━━━━━━━━━╋━━━━━━━━━━━╋━━━━━━━━━━━╋━━━━━━━━━━━╋━━━━━━━━━━━╋━━━━━━━━━━━┓
// ┃           ┃           ┃   CTRL    ┃   SHIFT   ┃    ALT    ┃           ┃   ┃           ┃           ┃           ┃           ┃           ┃           ┃
// ┗━━━━━━━━━━━┻━━━━━━━━━━━┻━━━━━━━━━━━╋━━━━━━━━━━━╋━━━━━━━━━━━╋━━━━━━━━━━━┫   ┣━━━━━━━━━━━╋━━━━━━━━━━━╋━━━━━━━━━━━╋━━━━━━━━━━━┻━━━━━━━━━━━┻━━━━━━━━━━━┛
//                                     ┃           ┃           ┃           ┃   ┃   RESIZE  ┃           ┃           ┃
//                                     ┗━━━━━━━━━━━┻━━━━━━━━━━━┻━━━━━━━━━━━┛   ┗━━━━━━━━━━━┻━━━━━━━━━━━┻━━━━━━━━━━━┛
 bindings = <
// ╷           ╷           ╷           ╷           ╷           ╷           ╷   ╷           ╷           ╷           ╷           ╷           ╷           ╷

                &kp LG(LC(ESC))  &kp LG(LS(ESC))  &none  &none  &kp LG(GRAVE)   &none  &kp LG(HOME)  &kp LG(UP)    &kp LG(END)    &kp LG(PG_UP)
                &kp LGUI    &kp LALT    &kp LSHFT   &kp LCTRL   &kp LG(LS(GRAVE))  &none  &kp LG(LEFT)  &kp LG(DOWN)  &kp LG(RIGHT)  &kp LG(PG_DN)
    &none       &none       &kp LCTRL   &kp LSHFT   &kp LALT    &none           &none       &none       &none         &none       &none       &none
                                        &to BASE    &trans      &trans          &mo TSIZ   &trans      &trans
                        >;
                };

// ▄▄▄▄▄▄▄▄▄▄▄▄▄▄▄▄▄▄▄▄▄▄▄▄▄▄▄▄▄▄▄▄▄▄▄▄▄▄▄▄▄▄▄▄▄▄▄▄▄▄▄▄▄▄▄▄▄▄▄▄▄▄▄▄▄▄▄▄▄▄▄▄▄▄▄▄▄▄▄▄▄▄▄▄▄▄▄▄▄▄▄▄▄▄▄▄▄▄▄▄▄▄▄▄▄▄▄▄▄▄▄▄▄▄▄▄▄▄▄▄▄▄▄▄▄▄▄▄▄▄▄▄▄▄▄▄▄▄▄▄▄▄▄▄▄▄▄▄▄

                tilesize_layer {
// ┏━━━━━━━━━━━━━━━━━━━━━━━━━━━━━━━━━━━━━━━┓
label= "TSIZ"                              ;
// ┗━━━━━━━━━━━━━━━━━━━━━━━━━━━━━━━━━━━━━━━┛
//             ┏━━━━━━━━━━━┳━━━━━━━━━━━┳━━━━━━━━━━━┳━━━━━━━━━━━┳━━━━━━━━━━━┓   ┏━━━━━━━━━━━┳━━━━━━━━━━━┳━━━━━━━━━━━┳━━━━━━━━━━━┳━━━━━━━━━━━┓
//             ┃           ┃           ┃           ┃           ┃           ┃   ┃           ┃           ┃  SIZE UP  ┃           ┃           ┃
//             ┣━━━━━━━━━━━╋━━━━━━━━━━━╋━━━━━━━━━━━╋━━━━━━━━━━━╋━━━━━━━━━━━┫   ┣━━━━━━━━━━━╋━━━━━━━━━━━╋━━━━━━━━━━━╋━━━━━━━━━━━╋━━━━━━━━━━━┫
//             ┃           ┃           ┃           ┃           ┃           ┃   ┃           ┃ SIZE LEFT ┃ SIZE DOWN ┃ SIZERIGHT ┃           ┃
// ┏━━━━━━━━━━━╋━━━━━━━━━━━╋━━━━━━━━━━━╋━━━━━━━━━━━╋━━━━━━━━━━━╋━━━━━━━━━━━┫   ┣━━━━━━━━━━━╋━━━━━━━━━━━╋━━━━━━━━━━━╋━━━━━━━━━━━╋━━━━━━━━━━━╋━━━━━━━━━━━┓
// ┃           ┃           ┃           ┃           ┃           ┃           ┃   ┃           ┃           ┃           ┃           ┃           ┃           ┃
// ┗━━━━━━━━━━━┻━━━━━━━━━━━┻━━━━━━━━━━━╋━━━━━━━━━━━╋━━━━━━━━━━━╋━━━━━━━━━━━┫   ┣━━━━━━━━━━━╋━━━━━━━━━━━╋━━━━━━━━━━━╋━━━━━━━━━━━┻━━━━━━━━━━━┻━━━━━━━━━━━┛
//                                     ┃           ┃           ┃           ┃   ┃           ┃           ┃           ┃
//                                     ┗━━━━━━━━━━━┻━━━━━━━━━━━┻━━━━━━━━━━━┛   ┗━━━━━━━━━━━┻━━━━━━━━━━━┻━━━━━━━━━━━┛
 bindings = <
// ╷           ╷           ╷           ╷           ╷           ╷           ╷   ╷           ╷           ╷           ╷           ╷           ╷           ╷

                &none       &none       &none       &none       &none           &none       &none       &kp LG(PLUS)  &none     &none
                &none       &none       &none       &none       &none           &none  &kp LG(LS(MINUS))  &kp LG(MINUS)  &kp LG(LS(PLUS))  &none
    &trans      &trans      &none       &none       &none       &none           &none       &none       &none         &none     &none       &none
                                        &to BASE    &trans      &trans          &trans      &trans      &trans
                        >;
                };

// ▄▄▄▄▄▄▄▄▄▄▄▄▄▄▄▄▄▄▄▄▄▄▄▄▄▄▄▄▄▄▄▄▄▄▄▄▄▄▄▄▄▄▄▄▄▄▄▄▄▄▄▄▄▄▄▄▄▄▄▄▄▄▄▄▄▄▄▄▄▄▄▄▄▄▄▄▄▄▄▄▄▄▄▄▄▄▄▄▄▄▄▄▄▄▄▄▄▄▄▄▄▄▄▄▄▄▄▄▄▄▄▄▄▄▄▄▄▄▄▄▄▄▄▄▄▄▄▄▄▄▄▄▄▄▄▄▄▄▄▄▄▄▄▄▄▄▄▄▄

                norway_layer {
// ┏━━━━━━━━━━━━━━━━━━━━━━━━━━━━━━━━━━━━━━━┓
label= "NORW"                              ;
// ┗━━━━━━━━━━━━━━━━━━━━━━━━━━━━━━━━━━━━━━━┛
//             ┏━━━━━━━━━━━┳━━━━━━━━━━━┳━━━━━━━━━━━┳━━━━━━━━━━━┳━━━━━━━━━━━┓   ┏━━━━━━━━━━━┳━━━━━━━━━━━┳━━━━━━━━━━━┳━━━━━━━━━━━┳━━━━━━━━━━━┓
//             ┃           ┃           ┃           ┃           ┃           ┃   ┃           ┃           ┃           ┃           ┃     Å     ┃
//             ┣━━━━━━━━━━━╋━━━━━━━━━━━╋━━━━━━━━━━━╋━━━━━━━━━━━╋━━━━━━━━━━━┫   ┣━━━━━━━━━━━╋━━━━━━━━━━━╋━━━━━━━━━━━╋━━━━━━━━━━━╋━━━━━━━━━━━┫
//             ┃           ┃           ┃           ┃           ┃           ┃   ┃           ┃           ┃           ┃     Ø     ┃     Æ     ┃
// ┏━━━━━━━━━━━╋━━━━━━━━━━━╋━━━━━━━━━━━╋━━━━━━━━━━━╋━━━━━━━━━━━╋━━━━━━━━━━━┫   ┣━━━━━━━━━━━╋━━━━━━━━━━━╋━━━━━━━━━━━╋━━━━━━━━━━━╋━━━━━━━━━━━╋━━━━━━━━━━━┓
// ┃           ┃           ┃           ┃           ┃           ┃           ┃   ┃           ┃           ┃           ┃           ┃           ┃           ┃
// ┗━━━━━━━━━━━┻━━━━━━━━━━━┻━━━━━━━━━━━╋━━━━━━━━━━━╋━━━━━━━━━━━╋━━━━━━━━━━━┫   ┣━━━━━━━━━━━╋━━━━━━━━━━━╋━━━━━━━━━━━╋━━━━━━━━━━━┻━━━━━━━━━━━┻━━━━━━━━━━━┛
//                                     ┃           ┃           ┃           ┃   ┃           ┃           ┃           ┃
//                                     ┗━━━━━━━━━━━┻━━━━━━━━━━━┻━━━━━━━━━━━┛   ┗━━━━━━━━━━━┻━━━━━━━━━━━┻━━━━━━━━━━━┛
 bindings = <
// ╷           ╷           ╷           ╷           ╷           ╷           ╷   ╷           ╷           ╷           ╷           ╷           ╷           ╷

                &trans      &trans      &trans      &trans      &trans          &trans      &trans      &trans      &trans      &mc_aa
                &trans      &trans      &trans      &trans      &trans          &trans      &trans      &trans      &kp RA(O)   &kp RA(A)
    &trans      &trans      &trans      &trans      &trans      &trans          &trans      &trans      &trans      &trans      &trans   &trans
                                        &to BASE    &trans      &trans          &trans      &trans      &trans
                        >;
                };

// ▄▄▄▄▄▄▄▄▄▄▄▄▄▄▄▄▄▄▄▄▄▄▄▄▄▄▄▄▄▄▄▄▄▄▄▄▄▄▄▄▄▄▄▄▄▄▄▄▄▄▄▄▄▄▄▄▄▄▄▄▄▄▄▄▄▄▄▄▄▄▄▄▄▄▄▄▄▄▄▄▄▄▄▄▄▄▄▄▄▄▄▄▄▄▄▄▄▄▄▄▄▄▄▄▄▄▄▄▄▄▄▄▄▄▄▄▄▄▄▄▄▄▄▄▄▄▄▄▄▄▄▄▄▄▄▄▄▄▄▄▄▄▄▄▄▄▄▄▄

                emoji_layer {
// ┏━━━━━━━━━━━━━━━━━━━━━━━━━━━━━━━━━━━━━━━┓
label= "EMOJ"                              ;
// ┗━━━━━━━━━━━━━━━━━━━━━━━━━━━━━━━━━━━━━━━┛
//             ┏━━━━━━━━━━━┳━━━━━━━━━━━┳━━━━━━━━━━━┳━━━━━━━━━━━┳━━━━━━━━━━━┓   ┏━━━━━━━━━━━┳━━━━━━━━━━━┳━━━━━━━━━━━┳━━━━━━━━━━━┳━━━━━━━━━━━┓
//             ┃           ┃           ┃           ┃           ┃           ┃   ┃           ┃           ┃           ┃           ┃           ┃
//             ┣━━━━━━━━━━━╋━━━━━━━━━━━╋━━━━━━━━━━━╋━━━━━━━━━━━╋━━━━━━━━━━━┫   ┣━━━━━━━━━━━╋━━━━━━━━━━━╋━━━━━━━━━━━╋━━━━━━━━━━━╋━━━━━━━━━━━┫
//             ┃           ┃           ┃           ┃           ┃           ┃   ┃           ┃           ┃           ┃           ┃           ┃
// ┏━━━━━━━━━━━╋━━━━━━━━━━━╋━━━━━━━━━━━╋━━━━━━━━━━━╋━━━━━━━━━━━╋━━━━━━━━━━━┫   ┣━━━━━━━━━━━╋━━━━━━━━━━━╋━━━━━━━━━━━╋━━━━━━━━━━━╋━━━━━━━━━━━╋━━━━━━━━━━━┓
// ┃           ┃           ┃           ┃           ┃           ┃           ┃   ┃           ┃           ┃           ┃           ┃           ┃           ┃
// ┗━━━━━━━━━━━┻━━━━━━━━━━━┻━━━━━━━━━━━╋━━━━━━━━━━━╋━━━━━━━━━━━╋━━━━━━━━━━━┫   ┣━━━━━━━━━━━╋━━━━━━━━━━━╋━━━━━━━━━━━╋━━━━━━━━━━━┻━━━━━━━━━━━┻━━━━━━━━━━━┛
//                                     ┃           ┃           ┃           ┃   ┃           ┃           ┃           ┃
//                                     ┗━━━━━━━━━━━┻━━━━━━━━━━━┻━━━━━━━━━━━┛   ┗━━━━━━━━━━━┻━━━━━━━━━━━┻━━━━━━━━━━━┛
 bindings = <
// ╷           ╷           ╷           ╷           ╷           ╷           ╷   ╷           ╷           ╷           ╷           ╷           ╷           ╷

                &trans      &trans      &trans      &trans      &trans          &trans      &trans      &trans      &trans      &trans
                &trans      &trans      &trans      &trans      &trans          &trans      &trans      &trans      &trans      &trans
    &trans      &trans      &trans      &trans      &trans      &trans          &trans      &trans      &trans      &trans      &trans   &trans
                                        &to BASE    &trans      &trans          &trans      &trans      &trans
                        >;
                };

// ▄▄▄▄▄▄▄▄▄▄▄▄▄▄▄▄▄▄▄▄▄▄▄▄▄▄▄▄▄▄▄▄▄▄▄▄▄▄▄▄▄▄▄▄▄▄▄▄▄▄▄▄▄▄▄▄▄▄▄▄▄▄▄▄▄▄▄▄▄▄▄▄▄▄▄▄▄▄▄▄▄▄▄▄▄▄▄▄▄▄▄▄▄▄▄▄▄▄▄▄▄▄▄▄▄▄▄▄▄▄▄▄▄▄▄▄▄▄▄▄▄▄▄▄▄▄▄▄▄▄▄▄▄▄▄▄▄▄▄▄▄▄▄▄▄▄▄▄▄

                select_layer {
// ┏━━━━━━━━━━━━━━━━━━━━━━━━━━━━━━━━━━━━━━━┓
label= "SELC"                              ;
// ┗━━━━━━━━━━━━━━━━━━━━━━━━━━━━━━━━━━━━━━━┛
//             ┏━━━━━━━━━━━┳━━━━━━━━━━━┳━━━━━━━━━━━┳━━━━━━━━━━━┳━━━━━━━━━━━┓   ┏━━━━━━━━━━━┳━━━━━━━━━━━┳━━━━━━━━━━━┳━━━━━━━━━━━┳━━━━━━━━━━━┓
//             ┃  DEL TOP  ┃ DEL HOME  ┃           ┃ DEL END   ┃  DEL BTTM ┃   ┃  SEL TOP  ┃ SEL HOME  ┃           ┃ SEL END   ┃ SEL BTTM  ┃
//             ┣━━━━━━━━━━━╋━━━━━━━━━━━╋━━━━━━━━━━━╋━━━━━━━━━━━╋━━━━━━━━━━━┫   ┣━━━━━━━━━━━╋━━━━━━━━━━━╋━━━━━━━━━━━╋━━━━━━━━━━━╋━━━━━━━━━━━┫
//             ┃           ┃ DEL LEFT  ┃           ┃ DEL RIGHT ┃           ┃   ┃           ┃ SEL LEFT  ┃           ┃ SEL RIGHT ┃           ┃
// ┏━━━━━━━━━━━╋━━━━━━━━━━━╋━━━━━━━━━━━╋━━━━━━━━━━━╋━━━━━━━━━━━╋━━━━━━━━━━━┫   ┣━━━━━━━━━━━╋━━━━━━━━━━━╋━━━━━━━━━━━╋━━━━━━━━━━━╋━━━━━━━━━━━╋━━━━━━━━━━━┓
// ┃           ┃           ┃           ┃           ┃ DEL BTTM  ┃           ┃   ┃           ┃           ┃           ┃ SEL BTTM  ┃           ┃           ┃
// ┗━━━━━━━━━━━┻━━━━━━━━━━━┻━━━━━━━━━━━╋━━━━━━━━━━━╋━━━━━━━━━━━╋━━━━━━━━━━━┫   ┣━━━━━━━━━━━╋━━━━━━━━━━━╋━━━━━━━━━━━╋━━━━━━━━━━━┻━━━━━━━━━━━┻━━━━━━━━━━━┛
//                                     ┃           ┃           ┃           ┃   ┃           ┃   TERM    ┃           ┃
//                                     ┗━━━━━━━━━━━┻━━━━━━━━━━━┻━━━━━━━━━━━┛   ┗━━━━━━━━━━━┻━━━━━━━━━━━┻━━━━━━━━━━━┛
 bindings = <
// ╷           ╷           ╷           ╷           ╷           ╷           ╷   ╷           ╷           ╷           ╷           ╷           ╷           ╷

                &mc_dtp     &mc_dhm       &none     &mc_den     &mc_dbm         &kp LC(LS(HOME))  &kp LS(HOME)  &none  &kp LS(END)  &kp LC(LS(END))
                &none       &kp LC(BSPC)  &none     &kp LC(DEL)  &none          &none   &kp LC(LS(LEFT))  &none     &kp LC(LS(RIGHT))  &none
    &trans      &none       &none       &none       &mc_dbm     &none           &none       &none       &none       &none       &kp LC(LS(END))  &trans
                                        &to BASE    &trans      &trans          &trans      &mo TERM    &trans
                        >;
                };

// ▄▄▄▄▄▄▄▄▄▄▄▄▄▄▄▄▄▄▄▄▄▄▄▄▄▄▄▄▄▄▄▄▄▄▄▄▄▄▄▄▄▄▄▄▄▄▄▄▄▄▄▄▄▄▄▄▄▄▄▄▄▄▄▄▄▄▄▄▄▄▄▄▄▄▄▄▄▄▄▄▄▄▄▄▄▄▄▄▄▄▄▄▄▄▄▄▄▄▄▄▄▄▄▄▄▄▄▄▄▄▄▄▄▄▄▄▄▄▄▄▄▄▄▄▄▄▄▄▄▄▄▄▄▄▄▄▄▄▄▄▄▄▄▄▄▄▄▄▄

                terminal_layer {
// ┏━━━━━━━━━━━━━━━━━━━━━━━━━━━━━━━━━━━━━━━┓
label= "TERM"                              ;
// ┗━━━━━━━━━━━━━━━━━━━━━━━━━━━━━━━━━━━━━━━┛
//             ┏━━━━━━━━━━━┳━━━━━━━━━━━┳━━━━━━━━━━━┳━━━━━━━━━━━┳━━━━━━━━━━━┓   ┏━━━━━━━━━━━┳━━━━━━━━━━━┳━━━━━━━━━━━┳━━━━━━━━━━━┳━━━━━━━━━━━┓
//             ┃           ┃ DEL HOME  ┃           ┃ DEL END   ┃           ┃   ┃           ┃  GO HOME  ┃           ┃  GO END   ┃           ┃
//             ┣━━━━━━━━━━━╋━━━━━━━━━━━╋━━━━━━━━━━━╋━━━━━━━━━━━╋━━━━━━━━━━━┫   ┣━━━━━━━━━━━╋━━━━━━━━━━━╋━━━━━━━━━━━╋━━━━━━━━━━━╋━━━━━━━━━━━┫
//             ┃           ┃ DEL LEFT  ┃           ┃ DEL RIGHT ┃           ┃   ┃           ┃  GO LEFT  ┃           ┃  GO RIGHT ┃           ┃
// ┏━━━━━━━━━━━╋━━━━━━━━━━━╋━━━━━━━━━━━╋━━━━━━━━━━━╋━━━━━━━━━━━╋━━━━━━━━━━━┫   ┣━━━━━━━━━━━╋━━━━━━━━━━━╋━━━━━━━━━━━╋━━━━━━━━━━━╋━━━━━━━━━━━╋━━━━━━━━━━━┓
// ┃           ┃           ┃           ┃           ┃           ┃           ┃   ┃           ┃           ┃           ┃           ┃           ┃           ┃
// ┗━━━━━━━━━━━┻━━━━━━━━━━━┻━━━━━━━━━━━╋━━━━━━━━━━━╋━━━━━━━━━━━╋━━━━━━━━━━━┫   ┣━━━━━━━━━━━╋━━━━━━━━━━━╋━━━━━━━━━━━╋━━━━━━━━━━━┻━━━━━━━━━━━┻━━━━━━━━━━━┛
//                                     ┃           ┃           ┃           ┃   ┃           ┃           ┃           ┃
//                                     ┗━━━━━━━━━━━┻━━━━━━━━━━━┻━━━━━━━━━━━┛   ┗━━━━━━━━━━━┻━━━━━━━━━━━┻━━━━━━━━━━━┛
 bindings = <
// ╷           ╷           ╷           ╷           ╷           ╷           ╷   ╷           ╷           ╷           ╷           ╷           ╷           ╷

                &none       &kp LC(U)   &none       &kp LC(K)   &none           &none   &kp LCTRL(A)    &none    &kp LC(E)      &none
                &none       &kp LC(W)   &none       &kp LA(D)   &none           &none   &kp LA(B)       &none    &kp LA(F)      &none
    &trans      &none       &none       &none       &none       &none           &none   &kp LA(LC(A))   &kp LA(LC(D))  &kp LA(LC(R))  &none  &trans
                                        &to BASE    &trans      &trans          &trans      &trans      &trans
                        >;
                };

// ▄▄▄▄▄▄▄▄▄▄▄▄▄▄▄▄▄▄▄▄▄▄▄▄▄▄▄▄▄▄▄▄▄▄▄▄▄▄▄▄▄▄▄▄▄▄▄▄▄▄▄▄▄▄▄▄▄▄▄▄▄▄▄▄▄▄▄▄▄▄▄▄▄▄▄▄▄▄▄▄▄▄▄▄▄▄▄▄▄▄▄▄▄▄▄▄▄▄▄▄▄▄▄▄▄▄▄▄▄▄▄▄▄▄▄▄▄▄▄▄▄▄▄▄▄▄▄▄▄▄▄▄▄▄▄▄▄▄▄▄▄▄▄▄▄▄▄▄▄

                split_layer {
// ┏━━━━━━━━━━━━━━━━━━━━━━━━━━━━━━━━━━━━━━━┓
label= "SPLT"                              ;
// ┗━━━━━━━━━━━━━━━━━━━━━━━━━━━━━━━━━━━━━━━┛
//             ┏━━━━━━━━━━━┳━━━━━━━━━━━┳━━━━━━━━━━━┳━━━━━━━━━━━┳━━━━━━━━━━━┓   ┏━━━━━━━━━━━┳━━━━━━━━━━━┳━━━━━━━━━━━┳━━━━━━━━━━━┳━━━━━━━━━━━┓
//             ┃           ┃           ┃           ┃           ┃           ┃   ┃           ┃           ┃ SPLIT UP  ┃           ┃           ┃
//             ┣━━━━━━━━━━━╋━━━━━━━━━━━╋━━━━━━━━━━━╋━━━━━━━━━━━╋━━━━━━━━━━━┫   ┣━━━━━━━━━━━╋━━━━━━━━━━━╋━━━━━━━━━━━╋━━━━━━━━━━━╋━━━━━━━━━━━┫
//             ┃           ┃           ┃           ┃           ┃           ┃   ┃           ┃SPLIT LEFT ┃SPLIT DOWN ┃SPLIT RIGHT┃           ┃
// ┏━━━━━━━━━━━╋━━━━━━━━━━━╋━━━━━━━━━━━╋━━━━━━━━━━━╋━━━━━━━━━━━╋━━━━━━━━━━━┫   ┣━━━━━━━━━━━╋━━━━━━━━━━━╋━━━━━━━━━━━╋━━━━━━━━━━━╋━━━━━━━━━━━╋━━━━━━━━━━━┓
// ┃           ┃           ┃           ┃           ┃           ┃           ┃   ┃           ┃           ┃           ┃           ┃           ┃           ┃
// ┗━━━━━━━━━━━┻━━━━━━━━━━━┻━━━━━━━━━━━╋━━━━━━━━━━━╋━━━━━━━━━━━╋━━━━━━━━━━━┫   ┣━━━━━━━━━━━╋━━━━━━━━━━━╋━━━━━━━━━━━╋━━━━━━━━━━━┻━━━━━━━━━━━┻━━━━━━━━━━━┛
//                                     ┃           ┃           ┃           ┃   ┃           ┃           ┃           ┃
//                                     ┗━━━━━━━━━━━┻━━━━━━━━━━━┻━━━━━━━━━━━┛   ┗━━━━━━━━━━━┻━━━━━━━━━━━┻━━━━━━━━━━━┛
 bindings = <
// ╷           ╷           ╷           ╷           ╷           ╷           ╷   ╷           ╷           ╷           ╷           ╷           ╷           ╷

                &trans      &trans      &none       &trans      &trans          &none       &none       &mc_spu     &none       &none
                &trans      &trans      &none       &trans      &trans          &none       &mc_spl     &mc_spd     &mc_spr     &none
    &trans      &trans      &trans      &trans      &trans      &trans          &none       &none       &none       &none       &none       &trans
                                        &to BASE    &trans      &trans          &trans      &trans      &trans
                        >;
                };

// ▄▄▄▄▄▄▄▄▄▄▄▄▄▄▄▄▄▄▄▄▄▄▄▄▄▄▄▄▄▄▄▄▄▄▄▄▄▄▄▄▄▄▄▄▄▄▄▄▄▄▄▄▄▄▄▄▄▄▄▄▄▄▄▄▄▄▄▄▄▄▄▄▄▄▄▄▄▄▄▄▄▄▄▄▄▄▄▄▄▄▄▄▄▄▄▄▄▄▄▄▄▄▄▄▄▄▄▄▄▄▄▄▄▄▄▄▄▄▄▄▄▄▄▄▄▄▄▄▄▄▄▄▄▄▄▄▄▄▄▄▄▄▄▄▄▄▄▄▄

                qwerty_layer {
// ┏━━━━━━━━━━━━━━━━━━━━━━━━━━━━━━━━━━━━━━━┓
label= "QWER"                              ;
// ┗━━━━━━━━━━━━━━━━━━━━━━━━━━━━━━━━━━━━━━━┛
//             ┏━━━━━━━━━━━┳━━━━━━━━━━━┳━━━━━━━━━━━┳━━━━━━━━━━━┳━━━━━━━━━━━┓   ┏━━━━━━━━━━━┳━━━━━━━━━━━┳━━━━━━━━━━━┳━━━━━━━━━━━┳━━━━━━━━━━━┓
//             ┃     Q     ┃     W     ┃     E     ┃     R     ┃     T     ┃   ┃     Y     ┃     U     ┃    I      ┃     O     ┃     P     ┃
//             ┣━━━━━━━━━━━╋━━━━━━━━━━━╋━━━━━━━━━━━╋━━━━━━━━━━━╋━━━━━━━━━━━┫   ┣━━━━━━━━━━━╋━━━━━━━━━━━╋━━━━━━━━━━━╋━━━━━━━━━━━╋━━━━━━━━━━━┫
//             ┃     A     ┃     S     ┃     D     ┃     F     ┃           ┃   ┃     H     ┃     J     ┃     K     ┃     L     ┃     '     ┃
// ┏━━━━━━━━━━━╋━━━━━━━━━━━╋━━━━━━━━━━━╋━━━━━━━━━━━╋━━━━━━━━━━━╋━━━━━━━━━━━┫   ┣━━━━━━━━━━━╋━━━━━━━━━━━╋━━━━━━━━━━━╋━━━━━━━━━━━╋━━━━━━━━━━━╋━━━━━━━━━━━┓
// ┃   LSHFT   ┃           ┃           ┃           ┃     V     ┃     B     ┃   ┃     N     ┃     M     ┃           ┃           ┃           ┃    CTRL   ┃
// ┗━━━━━━━━━━━┻━━━━━━━━━━━┻━━━━━━━━━━━╋━━━━━━━━━━━╋━━━━━━━━━━━╋━━━━━━━━━━━┫   ┣━━━━━━━━━━━╋━━━━━━━━━━━╋━━━━━━━━━━━╋━━━━━━━━━━━┻━━━━━━━━━━━┻━━━━━━━━━━━┛
//                                     ┃           ┃   SPACE   ┃           ┃   ┃           ┃           ┃           ┃
//                                     ┗━━━━━━━━━━━┻━━━━━━━━━━━┻━━━━━━━━━━━┛   ┗━━━━━━━━━━━┻━━━━━━━━━━━┻━━━━━━━━━━━┛
 bindings = <
// ╷           ╷           ╷           ╷           ╷           ╷           ╷   ╷           ╷           ╷           ╷           ╷           ╷           ╷

                &kp Q       &kb W       &kp E       &kp R       &kp T           &kp Y       &kp U       &kp I       &kp O       &kp P
                &kp A       &kp S       &kp D       &kp F       &trans          &kp H       &kp J       &kp K       &kp L       &kp SQT
    &kp LSHFT   &trans      &trans      &trans      &kp V       &kp B           &kp N       &kp M       &trans      &trans      &trans   &kp LCTRL
                                        &to BASE    &kp SPC     &trans          &trans      &trans      &trans
                        >;
                };

// ▄▄▄▄▄▄▄▄▄▄▄▄▄▄▄▄▄▄▄▄▄▄▄▄▄▄▄▄▄▄▄▄▄▄▄▄▄▄▄▄▄▄▄▄▄▄▄▄▄▄▄▄▄▄▄▄▄▄▄▄▄▄▄▄▄▄▄▄▄▄▄▄▄▄▄▄▄▄▄▄▄▄▄▄▄▄▄▄▄▄▄▄▄▄▄▄▄▄▄▄▄▄▄▄▄▄▄▄▄▄▄▄▄▄▄▄▄▄▄▄▄▄▄▄▄▄▄▄▄▄▄▄▄▄▄▄▄▄▄▄▄▄▄▄▄▄▄▄▄

                bluetooth_layer {
// ┏━━━━━━━━━━━━━━━━━━━━━━━━━━━━━━━━━━━━━━━┓
label= "BLUE"                              ;
// ┗━━━━━━━━━━━━━━━━━━━━━━━━━━━━━━━━━━━━━━━┛
//             ┏━━━━━━━━━━━┳━━━━━━━━━━━┳━━━━━━━━━━━┳━━━━━━━━━━━┳━━━━━━━━━━━┓   ┏━━━━━━━━━━━┳━━━━━━━━━━━┳━━━━━━━━━━━┳━━━━━━━━━━━┳━━━━━━━━━━━┓
//             ┃ BT DISC 0 ┃ BT DISC 1 ┃ BT DISC 2 ┃ BT DISC 3 ┃           ┃   ┃ BTCLEARALL┃           ┃  BT NEXT  ┃           ┃           ┃
//             ┣━━━━━━━━━━━╋━━━━━━━━━━━╋━━━━━━━━━━━╋━━━━━━━━━━━╋━━━━━━━━━━━┫   ┣━━━━━━━━━━━╋━━━━━━━━━━━╋━━━━━━━━━━━╋━━━━━━━━━━━╋━━━━━━━━━━━┫
//             ┃ BT SEL 0  ┃ BT SEL 1  ┃ BT SEL 2  ┃ BT SEL 3  ┃           ┃   ┃  BT CLEAR ┃           ┃  BT PREV  ┃           ┃           ┃
// ┏━━━━━━━━━━━╋━━━━━━━━━━━╋━━━━━━━━━━━╋━━━━━━━━━━━╋━━━━━━━━━━━╋━━━━━━━━━━━┫   ┣━━━━━━━━━━━╋━━━━━━━━━━━╋━━━━━━━━━━━╋━━━━━━━━━━━╋━━━━━━━━━━━╋━━━━━━━━━━━┓
// ┃           ┃   RESET   ┃           ┃  OUT TOG  ┃           ┃  BOOTLOAD ┃   ┃ BOOTLOAD  ┃           ┃           ┃           ┃   RESET   ┃           ┃
// ┗━━━━━━━━━━━┻━━━━━━━━━━━┻━━━━━━━━━━━╋━━━━━━━━━━━╋━━━━━━━━━━━╋━━━━━━━━━━━┫   ┣━━━━━━━━━━━╋━━━━━━━━━━━╋━━━━━━━━━━━╋━━━━━━━━━━━┻━━━━━━━━━━━┻━━━━━━━━━━━┛
//                                     ┃           ┃           ┃           ┃   ┃           ┃           ┃           ┃
//                                     ┗━━━━━━━━━━━┻━━━━━━━━━━━┻━━━━━━━━━━━┛   ┗━━━━━━━━━━━┻━━━━━━━━━━━┻━━━━━━━━━━━┛
 bindings = <
// ╷           ╷           ╷           ╷           ╷           ╷           ╷   ╷           ╷           ╷           ╷           ╷           ╷           ╷

                &bt BT_DISC 0  &bt BT_DISC 1 &bt BT_DISC 2  &bt BT_DISC 3  &none  &bt CLR_ALL  &none    &bt BT_NXT   &none      &none
                &bt BT_SEL 0   &bt BT_SEL 1  &bt BT_SEL 2   &bt BT_SEL 3   &none  &bt CLR      &none    &bt BT_PRV   &none      &none
    &none       &td_rs         &none         &out OUT_TOG   &none     &td_bo      &td_bo       &none    &none        &none      &td_rs    &none
                                             &to BASE       &trans    &trans      &trans       &trans   &trans
                        >;
                };

// ▄▄▄▄▄▄▄▄▄▄▄▄▄▄▄▄▄▄▄▄▄▄▄▄▄▄▄▄▄▄▄▄▄▄▄▄▄▄▄▄▄▄▄▄▄▄▄▄▄▄▄▄▄▄▄▄▄▄▄▄▄▄▄▄▄▄▄▄▄▄▄▄▄▄▄▄▄▄▄▄▄▄▄▄▄▄▄▄▄▄▄▄▄▄▄▄▄▄▄▄▄▄▄▄▄▄▄▄▄▄▄▄▄▄▄▄▄▄▄▄▄▄▄▄▄▄▄▄▄▄▄▄▄▄▄▄▄▄▄▄▄▄▄▄▄▄▄▄▄

        };
};
